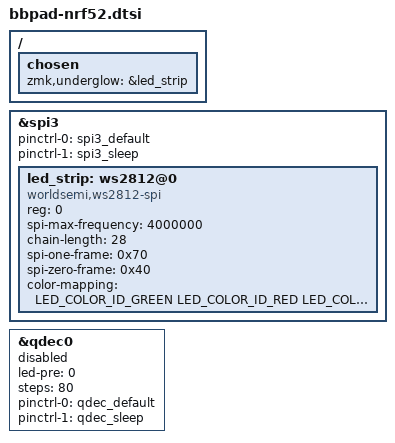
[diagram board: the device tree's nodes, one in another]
/*
 * Copyright (c) 2023 The ZMK Contributors
 *
 * SPDX-License-Identifier: MIT
 */

#include <dt-bindings/led/led.h>

&spi3 {
    status = "okay";

    pinctrl-0 = <&spi3_default>;
    pinctrl-1 = <&spi3_sleep>;
    pinctrl-names = "default", "sleep";

    led_strip: ws2812@0 {
        compatible = "worldsemi,ws2812-spi";

        /* SPI */
        reg = <0>; /* ignored, but necessary for SPI bindings */
        spi-max-frequency = <4000000>;

        /* WS2812 */
        chain-length = <28>; /* arbitrary; change at will */
        spi-one-frame = <0x70>;
        spi-zero-frame = <0x40>;

        color-mapping = <LED_COLOR_ID_GREEN LED_COLOR_ID_RED LED_COLOR_ID_BLUE>;
    };
};

qdec_encoder: &qdec0 {
    status = "disabled";
    led-pre = <0>;
    steps = <80>;
    pinctrl-0 = <&qdec_default>;
    pinctrl-1 = <&qdec_sleep>;
    pinctrl-names = "default", "sleep";
};

/ {
    chosen {
        zmk,underglow = &led_strip;
    };
};
